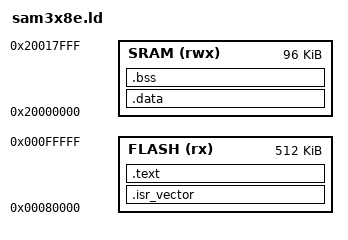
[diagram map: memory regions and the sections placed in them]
ENTRY(Reset_Handler)

MEMORY
{
    FLASH (rx) : ORIGIN = 0x00080000 , LENGTH = 512K
    SRAM (rwx) : ORIGIN = 0x20000000 , LENGTH = 96K
}

_estack = ORIGIN(SRAM) + LENGTH(SRAM);

SECTIONS
{
    .isr_vector ORIGIN(FLASH) :
    {
        KEEP(*(.isr_vector))
    } > FLASH

    .text :
    {
        . = ALIGN(4);
        *(.text*)
        *(.rodata*)
        . = ALIGN(4);
        _etext = .;
    } > FLASH

    .data : AT (_etext)
    {
        . = ALIGN(4);
        _sdata = .;
        *(.data*)
        . = ALIGN(4);
        _edata = .;
    } > SRAM

    _sidata = LOADADDR(.data);

    .bss (NOLOAD) :
    {
        . = ALIGN(4);
        _sbss = .;
        *(.bss*)
        *(COMMON)
        . = ALIGN(4);
        _ebss = .;
    } > SRAM
}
